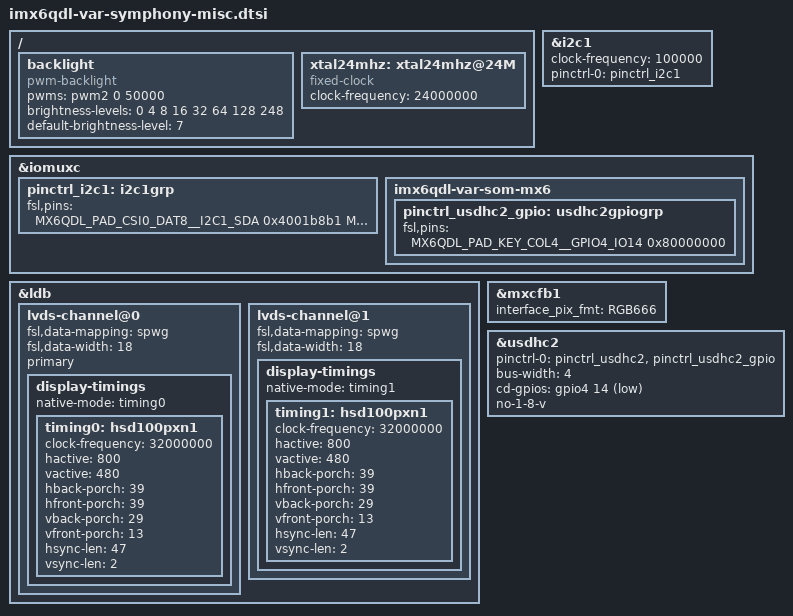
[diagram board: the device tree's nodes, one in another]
/*
 * Copyright (C) 2020 Variscite Ltd.
 *
 * This program is free software; you can redistribute it and/or modify
 * it under the terms of the GNU General Public License version 2 as
 * published by the Free Software Foundation.
 *
 * Settings for SymphonyBoard
 */

/ {
	backlight {
		compatible = "pwm-backlight";
		pwms = <&pwm2 0 50000>;
		brightness-levels = <0 4 8 16 32 64 128 248>;
		default-brightness-level = <7>;
		status = "okay";
	};

	xtal24mhz: xtal24mhz@24M {
		#clock-cells = <0>;
		compatible = "fixed-clock";
		clock-frequency = <24000000>;
	};
};

&i2c1 {
	clock-frequency = <100000>;
	pinctrl-names = "default";
	pinctrl-0 = <&pinctrl_i2c1>;
	status = "okay";
};

&iomuxc {
	pinctrl_i2c1: i2c1grp {
		fsl,pins = <
			MX6QDL_PAD_CSI0_DAT8__I2C1_SDA		0x4001b8b1
			MX6QDL_PAD_CSI0_DAT9__I2C1_SCL		0x4001b8b1
		>;
	};

	imx6qdl-var-som-mx6 {
		pinctrl_usdhc2_gpio: usdhc2gpiogrp {
			fsl,pins = <
				/* SDMMC2 CD */
				MX6QDL_PAD_KEY_COL4__GPIO4_IO14		0x80000000
			>;
		};
	};
};

&ldb {
	status = "okay";

	lvds-channel@0 {
		fsl,data-mapping = "spwg";
		fsl,data-width = <18>;
		primary;
		status = "okay";

		display-timings {
			native-mode = <&timing0>;
			timing0: hsd100pxn1 {
				clock-frequency = <32000000>;
				hactive = <800>;
				vactive = <480>;
				hback-porch = <39>;
				hfront-porch = <39>;
				vback-porch = <29>;
				vfront-porch = <13>;
				hsync-len = <47>;
				vsync-len = <2>;
			};
		};
	};

	lvds-channel@1 {
		fsl,data-mapping = "spwg";
		fsl,data-width = <18>;
		status = "okay";

		display-timings {
			native-mode = <&timing1>;
			timing1: hsd100pxn1 {
				clock-frequency = <32000000>;
				hactive = <800>;
				vactive = <480>;
				hback-porch = <39>;
				hfront-porch = <39>;
				vback-porch = <29>;
				vfront-porch = <13>;
				hsync-len = <47>;
				vsync-len = <2>;
			};
		};
	};
};

&mxcfb1 {
	interface_pix_fmt = "RGB666";
};

&usdhc2 {	/* uSDHC2, MMC/SD card */
	pinctrl-names = "default";
	pinctrl-0 = <&pinctrl_usdhc2>, <&pinctrl_usdhc2_gpio>;
	bus-width = <4>;
	cd-gpios = <&gpio4 14 GPIO_ACTIVE_LOW>;
	no-1-8-v;
	status = "okay";
};
